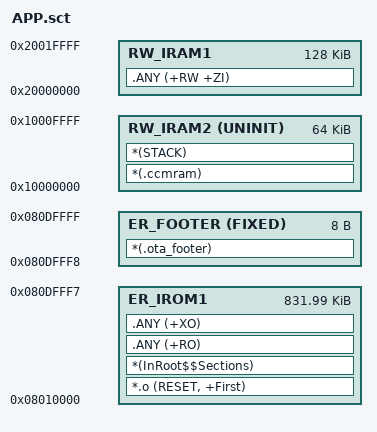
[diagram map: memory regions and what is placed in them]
; *************************************************************
; *** Scatter-Loading Description File generated by uVision ***
; *************************************************************
;
; APP partition: 0x08010000 ~ 0x080DFFFF (832 KB, 方案B：RUN 含原 BACKUP+DOWNLOAD)
; The last 8 bytes (0x080DFFF8 magic / 0x080DFFFC version) are linked from
; Config/app_footer.c, so Keil DAP direct flash is valid out of the box.
; OTA flow and Script/append_app_magic.py write the same values (idempotent).

LR_IROM1 0x08010000 0x000CFFF8  {    ; 主镜像 load region（代码+只读数据）
  ER_IROM1 0x08010000 0x000CFFF8  {  ; load address = execution address
   *.o (RESET, +First)
   *(InRoot$$Sections)
   .ANY (+RO)
   .ANY (+XO)
  }
  RW_IRAM1 0x20000000 0x00020000  {  ; RW data (128 KB: SRAM1+2；F407 无 SRAM3)
   .ANY (+RW +ZI)
  }
  RW_IRAM2 0x10000000 UNINIT 0x00010000  {  ; CCM RAM 64KB（FreeRTOS 堆/事件池/主栈，CPU-only）
   *(.ccmram)
   *(STACK)                                 ; 主栈放 CCM（避免压到不存在的 SRAM3）
  }
}

LR_FOOTER 0x080DFFF8 0x8  {          ; 独立 load region：RUN 尾部魔数 + 版本号
  ER_FOOTER 0x080DFFF8 FIXED 0x8  {
    *(.ota_footer)
  }
}
